# FM33A0XXER register map
File version: 1.0
CPU: SC000, little endian, no MPU, no FPU, 3 interrupt priority bits
Registers are 32-bit, read-write, reset 0x0 unless marked. A register's access mark holds for its fields unless they carry their own. Offsets are from the block's base; [hi:lo] are bit positions.

## PAE — PAE module information
Base 0x40001400
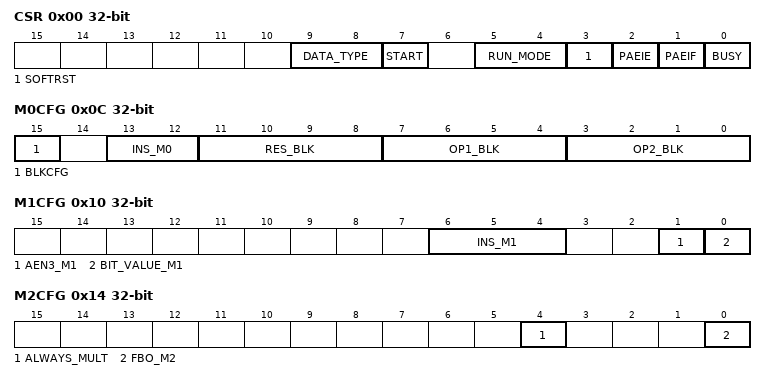
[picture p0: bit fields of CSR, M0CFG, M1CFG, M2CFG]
0x00 CSR
  [9:8] DATA_TYPE — DATA_TYPE field description
  [7] START wo — START field description
  [5:4] RUN_MODE — RUN_MODE field description
  [3] SOFTRST wo — SOFTRST field description
  [2] PAEIE — PAEIE field description
  [1] PAEIF — PAEIF field description
  [0] BUSY ro — BUSY field description
0x04 MLR
  [5:0] PAE_MLR — PAE_MLR field description
0x08 MPR
  [31:0] PAE_MPR wo — PAE_MPR field description
0x0C M0CFG
  [15] BLKCFG — BLKCFG field description
  [13:12] INS_M0 — INS_M0 field description
  [11:8] RES_BLK — RES_BLK field description
  [7:4] OP1_BLK — OP1_BLK field description
  [3:0] OP2_BLK — OP2_BLK field description
0x10 M1CFG
  [6:4] INS_M1 — INS_M1 field description
  [1] AEN3_M1 — AEN3_M1 field description
  [0] BIT_VALUE_M1 — BIT_VALUE_M1 field description
0x14 M2CFG
  [4] ALWAYS_MULT — ALWAYS_MULT field description
  [0] FBO_M2 — FBO_M2 field description
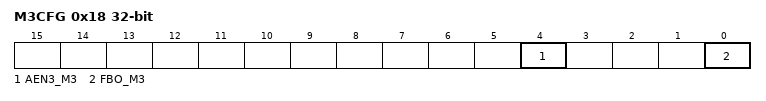
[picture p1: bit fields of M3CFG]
0x18 M3CFG
  [4] AEN3_M3 — AEN3_M3 field description
  [0] FBO_M3 — FBO_M3 field description
0x1C WORD
  [31:0] PAE_WORD wo — PAE_WORD field description

## HASH — HASH module information
Base 0x40001800
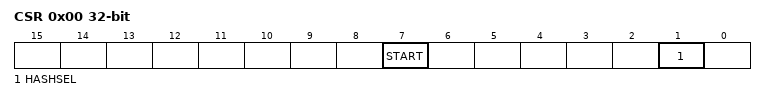
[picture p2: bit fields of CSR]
0x00 CSR — Hash Control and Status Register
  [7] START — START field description
  [1] HASHSEL — HASHSEL field description
0x04 DTR — Hash Data Type Register
  [1:0] DATA_TYPE — DATA_TYPE field description

## RNG — RNG module information
Base 0x40013C00
0x00 CR — Random Number Generator Control Register
  [0] EN — EN field description
0x04 DOR — Random Number Generator Data Output Register
  [31:0] OUT ro — OUT field description
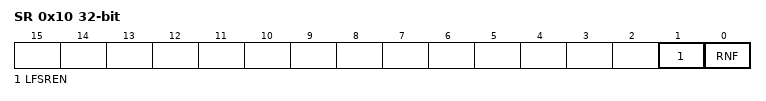
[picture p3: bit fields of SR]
0x10 SR — Random Number Generator Status Register
  [1] LFSREN ro — LFSREN field description
  [0] RNF — RNF field description
0x14 CRC_CR — CRC Control Register
  [0] CRCEN — CRCEN field description
0x18 CRC_DIR — CRC Data input Register
  [31:0] CRCIN — CRCIN field description
0x1C CRC_SR — CRC Status Register
  [0] CRCDONE — CRCDONE field description

## COMP — COMP module information
Base 0x40015400
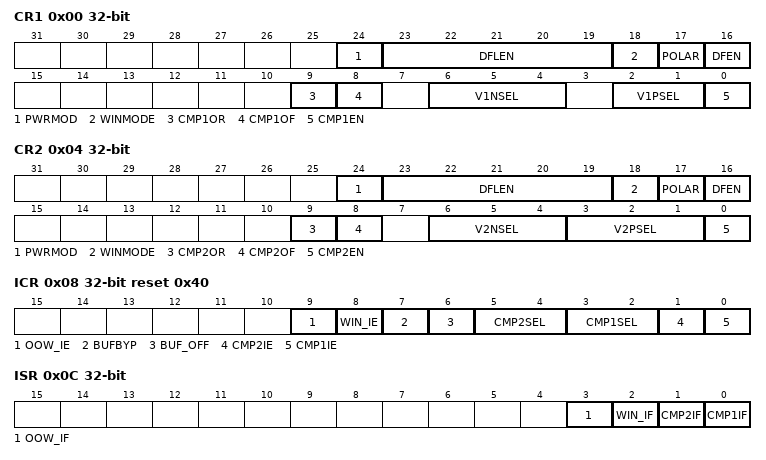
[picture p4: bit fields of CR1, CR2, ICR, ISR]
0x00 CR1
  [24] PWRMOD — PWRMOD field description
  [23:19] DFLEN — DFLEN field description
  [18] WINMODE — WINMODE field description
  [17] POLAR — POLAR field description
  [16] DFEN — DFEN field description
  [9] CMP1OR ro — CMP1OR field description
  [8] CMP1OF ro — CMP1OF field description
  [6:4] V1NSEL — V1NSEL field description
  [2:1] V1PSEL — V1PSEL field description
  [0] CMP1EN — CMP1EN field description
0x04 CR2
  [24] PWRMOD — PWRMOD field description
  [23:19] DFLEN — DFLEN field description
  [18] WINMODE — WINMODE field description
  [17] POLAR — POLAR field description
  [16] DFEN — DFEN field description
  [9] CMP2OR ro — CMP2OR field description
  [8] CMP2OF ro — CMP2OF field description
  [6:4] V2NSEL — V2NSEL field description
  [3:1] V2PSEL — V2PSEL field description
  [0] CMP2EN — CMP2EN field description
0x08 ICR reset 0x40
  [9] OOW_IE — OOW_IE field description
  [8] WIN_IE — WIN_IE field description
  [7] BUFBYP — BUFBYP field description
  [6] BUF_OFF — BUF_OFF field description
  [5:4] CMP2SEL — CMP2SEL field description
  [3:2] CMP1SEL — CMP1SEL field description
  [1] CMP2IE — CMP2IE field description
  [0] CMP1IE — CMP1IE field description
0x0C ISR
  [3] OOW_IF — OOW_IF field description
  [2] WIN_IF — WIN_IF field description
  [1] CMP2IF — CMP2IF field description
  [0] CMP1IF — CMP1IF field description
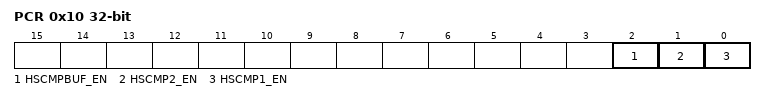
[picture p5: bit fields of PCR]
0x10 PCR
  [2] HSCMPBUF_EN — HSCMPBUF_EN field description
  [1] HSCMP2_EN — HSCMP2_EN field description
  [0] HSCMP1_EN — HSCMP1_EN field description

## I2C0 — I2C0 module information
Base 0x40012400
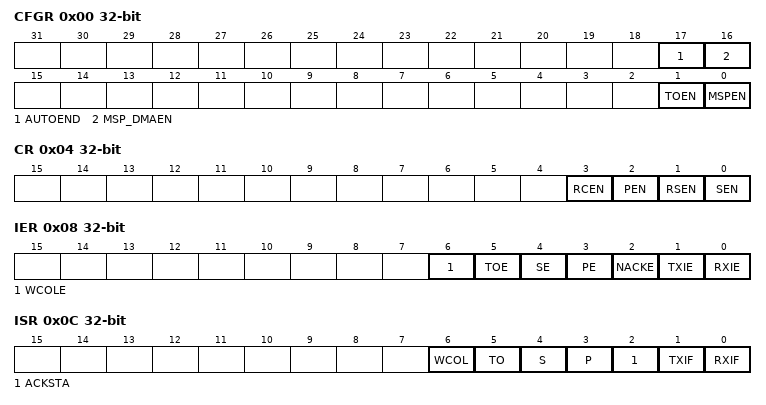
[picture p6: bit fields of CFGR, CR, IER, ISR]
0x00 CFGR — I2C0 Master Config Register
  [17] AUTOEND — AUTOEND field description
  [16] MSP_DMAEN — MSP_DMAEN field description
  [1] TOEN — TOEN field description
  [0] MSPEN — MSPEN field description
0x04 CR — I2C0 Master Control Register
  [3] RCEN — RCEN field description
  [2] PEN — PEN field description
  [1] RSEN — RSEN field description
  [0] SEN — SEN field description
0x08 IER — I2C0 Master Interrupt Enable Register
  [6] WCOLE — WCOLE field description
  [5] TOE — TOE field description
  [4] SE — SE field description
  [3] PE — PE field description
  [2] NACKE — NACKE field description
  [1] TXIE — TXIE field description
  [0] RXIE — RXIE field description
0x0C ISR — I2C0 Master Interrupt Status Register
  [6] WCOL — WCOL field description
  [5] TO — TO field description
  [4] S ro — S field description
  [3] P ro — P field description
  [2] ACKSTA — ACKSTA field description
  [1] TXIF — TXIF field description
  [0] RXIF — RXIF field description
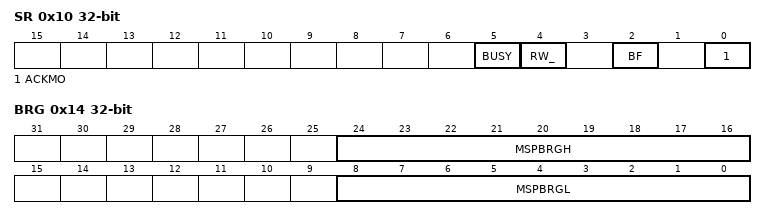
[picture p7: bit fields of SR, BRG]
0x10 SR — I2C0 Master Status Register
  [5] BUSY ro — BUSY field description
  [4] RW_ ro — RW_ field description
  [2] BF ro — BF field description
  [0] ACKMO — ACKMO field description
0x14 BRG — I2C0 Master Baud Rate Generation Register
  [24:16] MSPBRGH — MSPBRGH field description
  [8:0] MSPBRGL — MSPBRGL field description
0x18 BUF — I2C0 Master Buffer Register
  [7:0] MSPBUF — MSPBUF field description
0x1C TIMING — I2C0 Master Timing Register
  [8:0] SDAHD — SDAHD field description
0x20 TO reset 0xF00 — I2C0 Master Time-Out Register
  [11:0] TIMEOUT — TIMEOUT field description

## I2C1 — I2C1 module information
Base 0x40015000
Registers as I2C0 (with I2C0 read as I2C1).
